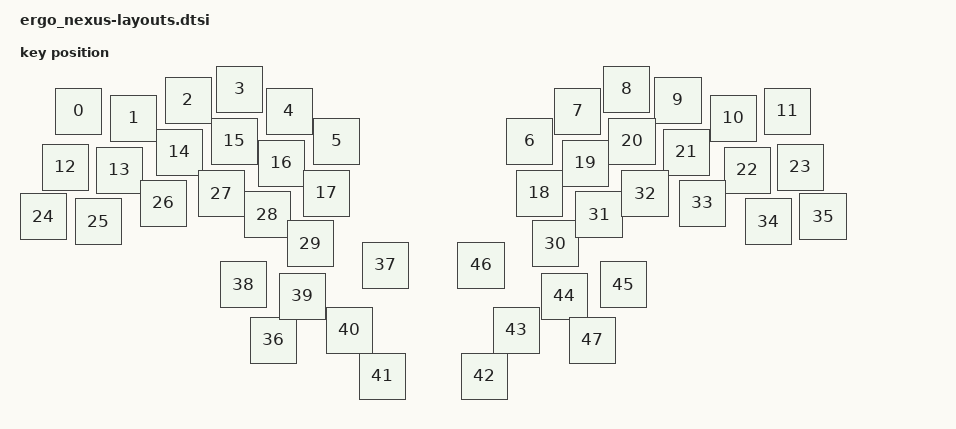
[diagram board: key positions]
/*
 * Generated by export_zmk_layout.py
 * Source: KiCad PCB Active Board
 */

#include <physical_layouts.dtsi>

/ {
    physical_layout0: physical_layout_0 {
        compatible = "zmk,physical-layout";
        display-name = "Default Layout";
        keys
         =  <&key_physical_attrs 100 100 71 44 0 121 94> /* K_L_16 */
        , <&key_physical_attrs 100 100 181 58 0 231 108> /* K_L_15 */
        , <&key_physical_attrs 100 100 290 22 0 340 72> /* K_L_14 */
        , <&key_physical_attrs 100 100 393 0 0 443 50> /* K_L_13 */
        , <&key_physical_attrs 100 100 492 44 0 542 94> /* K_L_12 */
        , <&key_physical_attrs 100 100 587 104 0 637 154> /* K_L_11 */
        , <&key_physical_attrs 100 100 973 104 0 1023 154> /* K_R_11 */
        , <&key_physical_attrs 100 100 1069 44 0 1119 94> /* K_R_12 */
        , <&key_physical_attrs 100 100 1167 0 0 1217 50> /* K_R_13 */
        , <&key_physical_attrs 100 100 1270 22 0 1320 72> /* K_R_14 */
        , <&key_physical_attrs 100 100 1380 58 0 1430 108> /* K_R_15 */
        , <&key_physical_attrs 100 100 1489 44 0 1539 94> /* K_R_16 */
        , <&key_physical_attrs 100 100 45 156 0 95 206> /* K_L_26 */
        , <&key_physical_attrs 100 100 152 162 0 202 212> /* K_L_25 */
        , <&key_physical_attrs 100 100 273 126 0 323 176> /* K_L_24 */
        , <&key_physical_attrs 100 100 382 104 0 432 154> /* K_L_23 */
        , <&key_physical_attrs 100 100 476 148 0 526 198> /* K_L_22 */
        , <&key_physical_attrs 100 100 567 208 0 617 258> /* K_L_21 */
        , <&key_physical_attrs 100 100 993 208 0 1043 258> /* K_R_21 */
        , <&key_physical_attrs 100 100 1084 148 0 1134 198> /* K_R_22 */
        , <&key_physical_attrs 100 100 1178 104 0 1228 154> /* K_R_23 */
        , <&key_physical_attrs 100 100 1287 126 0 1337 176> /* K_R_24 */
        , <&key_physical_attrs 100 100 1409 162 0 1459 212> /* K_R_25 */
        , <&key_physical_attrs 100 100 1515 156 0 1565 206> /* K_R_26 */
        , <&key_physical_attrs 100 100 0 255 0 50 305> /* K_L_36 */
        , <&key_physical_attrs 100 100 110 265 0 160 315> /* K_L_35 */
        , <&key_physical_attrs 100 100 241 228 0 291 278> /* K_L_34 */
        , <&key_physical_attrs 100 100 356 209 0 406 259> /* K_L_33 */
        , <&key_physical_attrs 100 100 449 251 0 499 301> /* K_L_32 */
        , <&key_physical_attrs 100 100 535 309 0 585 359> /* K_L_31 */
        , <&key_physical_attrs 100 100 1025 309 0 1075 359> /* K_R_31 */
        , <&key_physical_attrs 100 100 1112 251 0 1162 301> /* K_R_32 */
        , <&key_physical_attrs 100 100 1204 209 0 1254 259> /* K_R_33 */
        , <&key_physical_attrs 100 100 1319 228 0 1369 278> /* K_R_34 */
        , <&key_physical_attrs 100 100 1451 265 0 1501 315> /* K_R_35 */
        , <&key_physical_attrs 100 100 1560 255 0 1610 305> /* K_R_36 */
        , <&key_physical_attrs 100 100 461 502 0 511 552> /* RE2 */
        , <&key_physical_attrs 100 100 684 352 0 734 402> /* RE1 */
        , <&key_physical_attrs 100 100 400 391 0 450 441> /* K_L_44 */
        , <&key_physical_attrs 100 100 518 414 0 568 464> /* K_L_43 */
        , <&key_physical_attrs 100 100 613 482 0 663 532> /* K_L_42 */
        , <&key_physical_attrs 100 100 678 574 0 728 624> /* K_L_41 */
        , <&key_physical_attrs 100 100 882 574 0 932 624> /* K_R_41 */
        , <&key_physical_attrs 100 100 947 482 0 997 532> /* K_R_42 */
        , <&key_physical_attrs 100 100 1042 414 0 1092 464> /* K_R_43 */
        , <&key_physical_attrs 100 100 1161 391 0 1211 441> /* K_R_44 */
        , <&key_physical_attrs 100 100 876 352 0 926 402> /* RE3 */
        , <&key_physical_attrs 100 100 1099 502 0 1149 552> /* RE4 */
            ;
    };
};
